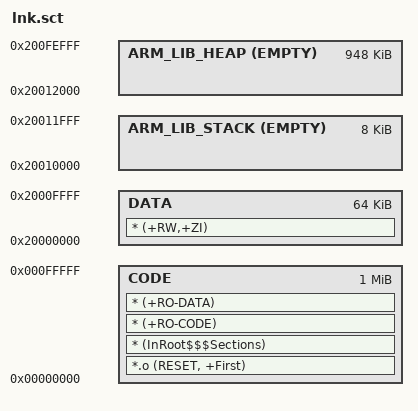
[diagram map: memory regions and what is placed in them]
#! armclang -E --target=arm-arm-none-eabi -mcpu=cortex-m0 -xc
; command above MUST be in first line (no comment above!)

/*
;-------- <<< Use Configuration Wizard in Context Menu >>> -------------------
*/

#include "mem_ARMCM0.h"

LOAD_REGION 0x0
{
/*

Not enough memory in the model so the read only tables are kept here.

*/
    CODE +0 0x100000
    {
        *.o (RESET, +First)
        * (InRoot$$$Sections)
        * (+RO-CODE) 
        * (+RO-DATA)                             
    }

    DATA 0x20000000 0x10000
    {
    * (+RW,+ZI)                         
    }

    ARM_LIB_STACK 0x20012000 ALIGN 64 EMPTY -0x00002000  
    {}
    ARM_LIB_HEAP 0x20012000 ALIGN 64 EMPTY 0x00ed000 
    {}

     
   
}

